# Basic_Timer_1 register map
Vendor: Texas Instruments
Peripheral module from a debugger description file (folder msp430).
Registers are 8-bit, access not given, no defined reset value unless marked. A register's access mark holds for its fields unless they carry their own. Offsets are as the file gives them; lines under a group give offsets from that group; [hi:lo] are bit positions; {n}, {i} and the like mark numbered series; 'fields as' and 'values as' point back to an identical list; <NAME> marks a mode.

## Basic_Timer
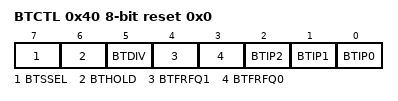
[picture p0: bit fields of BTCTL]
0x40 BTCTL rw reset 0x0 — Basic Timer Control
  [7] BTSSEL — fBT = fMCLK (main clock)
  [6] BTHOLD — BT1 is held if this bit is set
  [5] BTDIV — fCLK2 = ACLK:256
  [4] BTFRFQ1
  [3] BTFRFQ0
  [2] BTIP2
  [1] BTIP1
  [0] BTIP0
0x46 BTCNT1 — Basic Timer Count 1
0x47 BTCNT2 — Basic Timer Count 2
